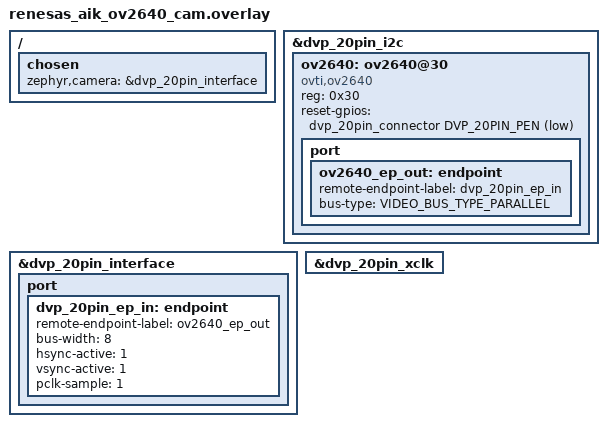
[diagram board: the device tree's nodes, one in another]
/*
 * Copyright (c) 2026 Renesas Electronics Corporation
 *
 * SPDX-License-Identifier: Apache-2.0
 */

#include <zephyr/dt-bindings/video/video-interfaces.h>

/ {
	chosen {
		zephyr,camera = &dvp_20pin_interface;
	};
};

&dvp_20pin_i2c {
	status = "okay";

	ov2640: ov2640@30 {
		compatible = "ovti,ov2640";
		reg = <0x30>;
		reset-gpios = <&dvp_20pin_connector DVP_20PIN_PEN GPIO_ACTIVE_LOW>;

		port {
			ov2640_ep_out: endpoint {
				remote-endpoint-label = "dvp_20pin_ep_in";
				bus-type = <VIDEO_BUS_TYPE_PARALLEL>;
			};
		};
	};
};

&dvp_20pin_interface {
	status = "okay";

	port {
		dvp_20pin_ep_in: endpoint {
			remote-endpoint-label = "ov2640_ep_out";
			bus-width = <8>;
			hsync-active = <1>;
			vsync-active = <1>;
			pclk-sample = <1>;
		};
	};
};

&dvp_20pin_xclk {
	status = "okay";
};
